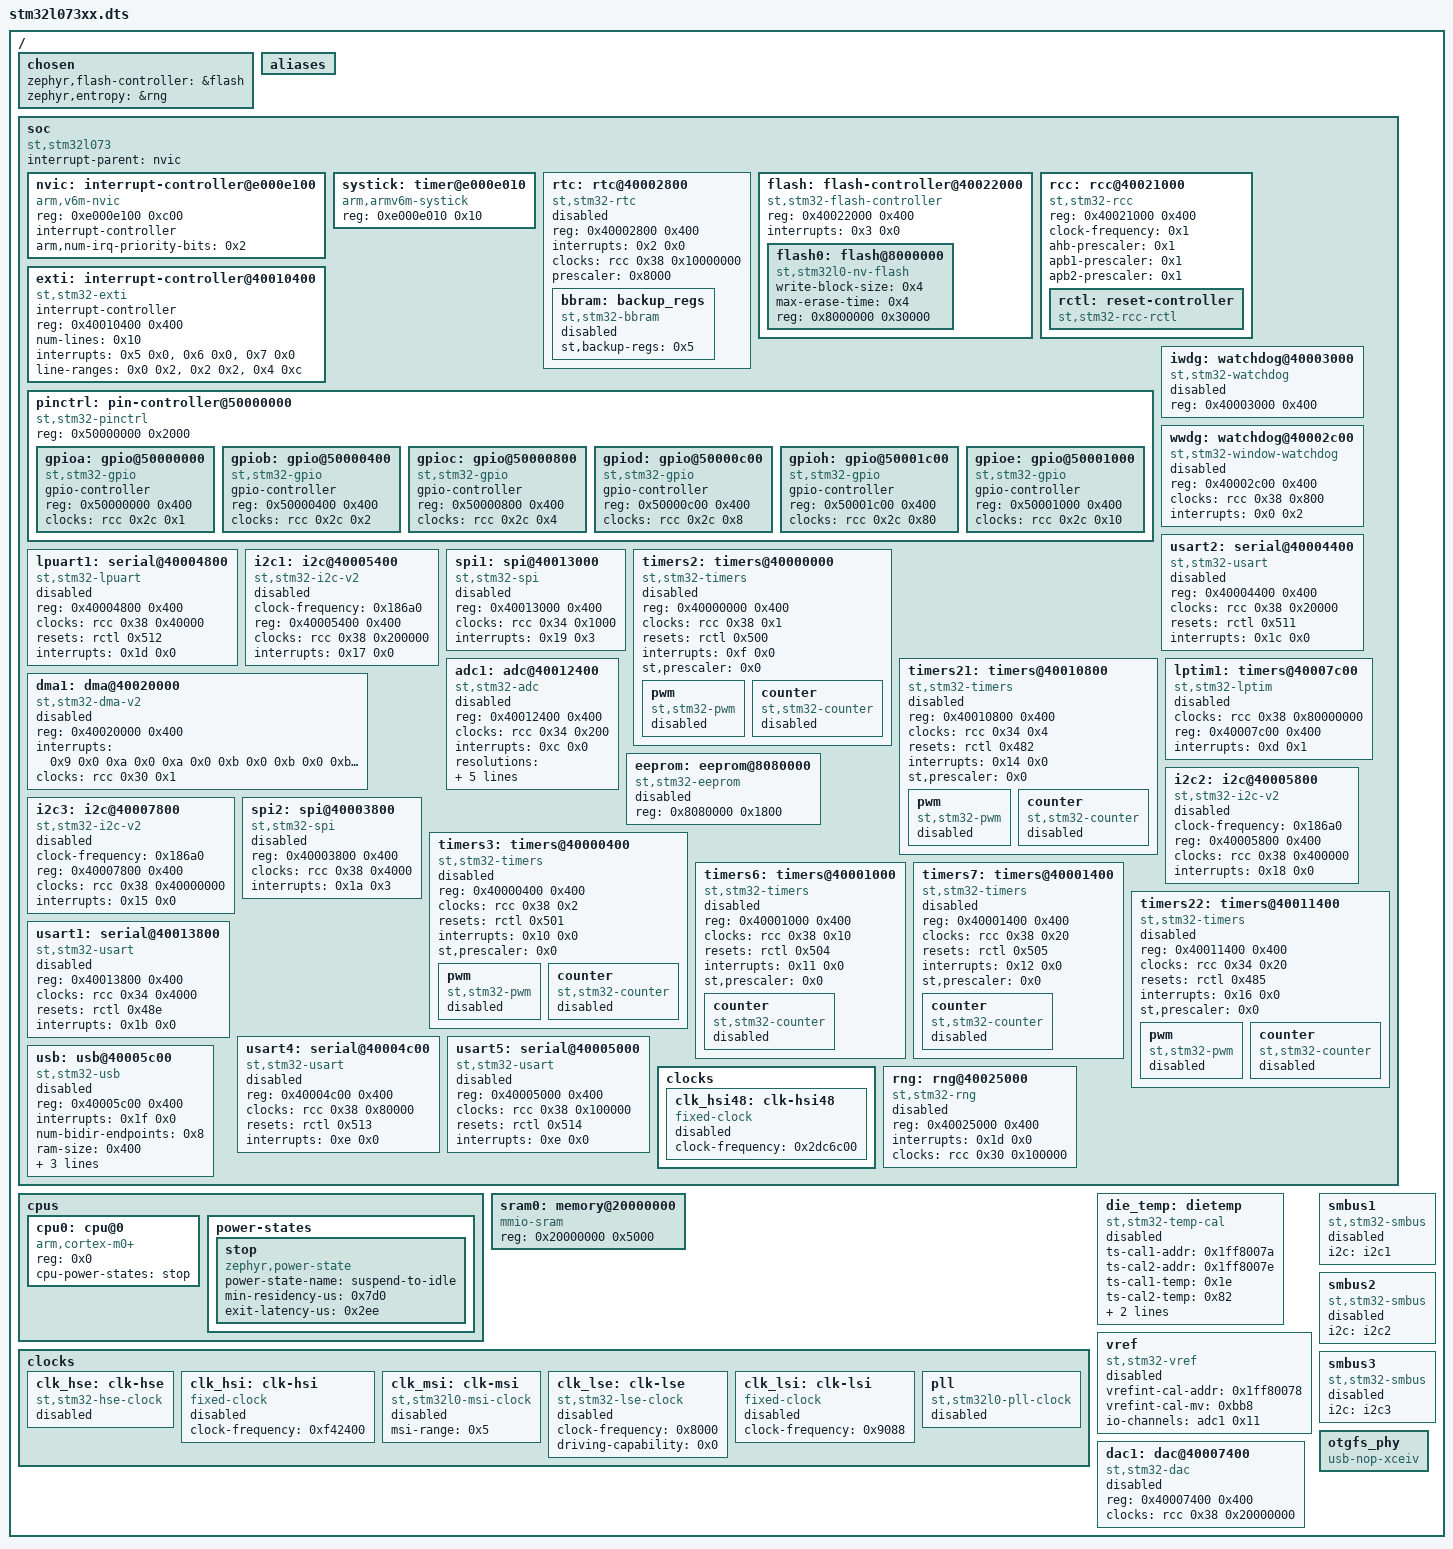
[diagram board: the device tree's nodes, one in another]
/dts-v1/;

/ {
	#address-cells = < 0x1 >;
	#size-cells = < 0x1 >;
	chosen {
		zephyr,flash-controller = &flash;
		zephyr,entropy = &rng;
	};
	aliases {
	};
	soc {
		#address-cells = < 0x1 >;
		#size-cells = < 0x1 >;
		compatible = "st,stm32l073", "st,stm32l0", "simple-bus";
		interrupt-parent = < &nvic >;
		ranges;
		nvic: interrupt-controller@e000e100 {
			#address-cells = < 0x1 >;
			compatible = "arm,v6m-nvic";
			reg = < 0xe000e100 0xc00 >;
			interrupt-controller;
			#interrupt-cells = < 0x2 >;
			arm,num-irq-priority-bits = < 0x2 >;
			phandle = < 0x1 >;
		};
		systick: timer@e000e010 {
			compatible = "arm,armv6m-systick";
			reg = < 0xe000e010 0x10 >;
		};
		rtc: rtc@40002800 {
			compatible = "st,stm32-rtc";
			reg = < 0x40002800 0x400 >;
			interrupts = < 0x2 0x0 >;
			clocks = < &rcc 0x38 0x10000000 >;
			prescaler = < 0x8000 >;
			status = "disabled";
			bbram: backup_regs {
				compatible = "st,stm32-bbram";
				st,backup-regs = < 0x5 >;
				status = "disabled";
			};
		};
		flash: flash-controller@40022000 {
			compatible = "st,stm32-flash-controller", "st,stm32f1-flash-controller";
			reg = < 0x40022000 0x400 >;
			interrupts = < 0x3 0x0 >;
			#address-cells = < 0x1 >;
			#size-cells = < 0x1 >;
			flash0: flash@8000000 {
				compatible = "st,stm32l0-nv-flash", "st,stm32-nv-flash", "soc-nv-flash";
				write-block-size = < 0x4 >;
				max-erase-time = < 0x4 >;
				reg = < 0x8000000 0x30000 >;
			};
		};
		rcc: rcc@40021000 {
			compatible = "st,stm32-rcc";
			#clock-cells = < 0x2 >;
			reg = < 0x40021000 0x400 >;
			clock-frequency = < 0x1 >;
			ahb-prescaler = < 0x1 >;
			apb1-prescaler = < 0x1 >;
			apb2-prescaler = < 0x1 >;
			phandle = < 0x2 >;
			rctl: reset-controller {
				compatible = "st,stm32-rcc-rctl";
				#reset-cells = < 0x1 >;
				phandle = < 0x3 >;
			};
		};
		exti: interrupt-controller@40010400 {
			compatible = "st,stm32-exti";
			interrupt-controller;
			#interrupt-cells = < 0x1 >;
			#address-cells = < 0x1 >;
			reg = < 0x40010400 0x400 >;
			num-lines = < 0x10 >;
			interrupts = < 0x5 0x0 >, < 0x6 0x0 >, < 0x7 0x0 >;
			interrupt-names = "line0-1", "line2-3", "line4-15";
			line-ranges = < 0x0 0x2 >, < 0x2 0x2 >, < 0x4 0xc >;
		};
		pinctrl: pin-controller@50000000 {
			compatible = "st,stm32-pinctrl";
			#address-cells = < 0x1 >;
			#size-cells = < 0x1 >;
			reg = < 0x50000000 0x2000 >;
			gpioa: gpio@50000000 {
				compatible = "st,stm32-gpio";
				gpio-controller;
				#gpio-cells = < 0x2 >;
				reg = < 0x50000000 0x400 >;
				clocks = < &rcc 0x2c 0x1 >;
			};
			gpiob: gpio@50000400 {
				compatible = "st,stm32-gpio";
				gpio-controller;
				#gpio-cells = < 0x2 >;
				reg = < 0x50000400 0x400 >;
				clocks = < &rcc 0x2c 0x2 >;
			};
			gpioc: gpio@50000800 {
				compatible = "st,stm32-gpio";
				gpio-controller;
				#gpio-cells = < 0x2 >;
				reg = < 0x50000800 0x400 >;
				clocks = < &rcc 0x2c 0x4 >;
			};
			gpiod: gpio@50000c00 {
				compatible = "st,stm32-gpio";
				gpio-controller;
				#gpio-cells = < 0x2 >;
				reg = < 0x50000c00 0x400 >;
				clocks = < &rcc 0x2c 0x8 >;
			};
			gpioh: gpio@50001c00 {
				compatible = "st,stm32-gpio";
				gpio-controller;
				#gpio-cells = < 0x2 >;
				reg = < 0x50001c00 0x400 >;
				clocks = < &rcc 0x2c 0x80 >;
			};
			gpioe: gpio@50001000 {
				compatible = "st,stm32-gpio";
				gpio-controller;
				#gpio-cells = < 0x2 >;
				reg = < 0x50001000 0x400 >;
				clocks = < &rcc 0x2c 0x10 >;
			};
		};
		iwdg: watchdog@40003000 {
			compatible = "st,stm32-watchdog";
			reg = < 0x40003000 0x400 >;
			status = "disabled";
		};
		wwdg: watchdog@40002c00 {
			compatible = "st,stm32-window-watchdog";
			reg = < 0x40002c00 0x400 >;
			clocks = < &rcc 0x38 0x800 >;
			interrupts = < 0x0 0x2 >;
			status = "disabled";
		};
		usart2: serial@40004400 {
			compatible = "st,stm32-usart", "st,stm32-uart";
			reg = < 0x40004400 0x400 >;
			clocks = < &rcc 0x38 0x20000 >;
			resets = < &rctl 0x511 >;
			interrupts = < 0x1c 0x0 >;
			status = "disabled";
		};
		lpuart1: serial@40004800 {
			compatible = "st,stm32-lpuart", "st,stm32-uart";
			reg = < 0x40004800 0x400 >;
			clocks = < &rcc 0x38 0x40000 >;
			resets = < &rctl 0x512 >;
			interrupts = < 0x1d 0x0 >;
			status = "disabled";
		};
		i2c1: i2c@40005400 {
			compatible = "st,stm32-i2c-v2";
			clock-frequency = < 0x186a0 >;
			#address-cells = < 0x1 >;
			#size-cells = < 0x0 >;
			reg = < 0x40005400 0x400 >;
			clocks = < &rcc 0x38 0x200000 >;
			interrupts = < 0x17 0x0 >;
			interrupt-names = "combined";
			status = "disabled";
			phandle = < 0x7 >;
		};
		spi1: spi@40013000 {
			compatible = "st,stm32-spi";
			#address-cells = < 0x1 >;
			#size-cells = < 0x0 >;
			reg = < 0x40013000 0x400 >;
			clocks = < &rcc 0x34 0x1000 >;
			interrupts = < 0x19 0x3 >;
			status = "disabled";
		};
		timers2: timers@40000000 {
			compatible = "st,stm32-timers";
			reg = < 0x40000000 0x400 >;
			clocks = < &rcc 0x38 0x1 >;
			resets = < &rctl 0x500 >;
			interrupts = < 0xf 0x0 >;
			interrupt-names = "global";
			st,prescaler = < 0x0 >;
			status = "disabled";
			pwm {
				compatible = "st,stm32-pwm";
				status = "disabled";
				#pwm-cells = < 0x3 >;
			};
			counter {
				compatible = "st,stm32-counter";
				status = "disabled";
			};
		};
		timers21: timers@40010800 {
			compatible = "st,stm32-timers";
			reg = < 0x40010800 0x400 >;
			clocks = < &rcc 0x34 0x4 >;
			resets = < &rctl 0x482 >;
			interrupts = < 0x14 0x0 >;
			interrupt-names = "global";
			st,prescaler = < 0x0 >;
			status = "disabled";
			pwm {
				compatible = "st,stm32-pwm";
				status = "disabled";
				#pwm-cells = < 0x3 >;
			};
			counter {
				compatible = "st,stm32-counter";
				status = "disabled";
			};
		};
		lptim1: timers@40007c00 {
			compatible = "st,stm32-lptim";
			clocks = < &rcc 0x38 0x80000000 >;
			#address-cells = < 0x1 >;
			#size-cells = < 0x0 >;
			reg = < 0x40007c00 0x400 >;
			interrupts = < 0xd 0x1 >;
			interrupt-names = "wakeup";
			status = "disabled";
		};
		adc1: adc@40012400 {
			compatible = "st,stm32-adc";
			reg = < 0x40012400 0x400 >;
			clocks = < &rcc 0x34 0x200 >;
			interrupts = < 0xc 0x0 >;
			status = "disabled";
			#io-channel-cells = < 0x1 >;
			resolutions = < 0x60630c 0x51630c 0x42630c 0x33630c >;
			sampling-times = < 0x2 0x4 0x8 0xd 0x14 0x28 0x50 0xa1 >;
			num-sampling-time-common-channels = < 0x1 >;
			st,adc-sequencer = < 0x0 >;
			phandle = < 0x6 >;
		};
		dma1: dma@40020000 {
			compatible = "st,stm32-dma-v2";
			#dma-cells = < 0x3 >;
			reg = < 0x40020000 0x400 >;
			interrupts = < 0x9 0x0 0xa 0x0 0xa 0x0 0xb 0x0 0xb 0x0 0xb 0x0 0xb 0x0 >;
			clocks = < &rcc 0x30 0x1 >;
			status = "disabled";
		};
		eeprom: eeprom@8080000 {
			compatible = "st,stm32-eeprom";
			status = "disabled";
			reg = < 0x8080000 0x1800 >;
		};
		i2c2: i2c@40005800 {
			compatible = "st,stm32-i2c-v2";
			clock-frequency = < 0x186a0 >;
			#address-cells = < 0x1 >;
			#size-cells = < 0x0 >;
			reg = < 0x40005800 0x400 >;
			clocks = < &rcc 0x38 0x400000 >;
			interrupts = < 0x18 0x0 >;
			interrupt-names = "combined";
			status = "disabled";
			phandle = < 0x8 >;
		};
		i2c3: i2c@40007800 {
			compatible = "st,stm32-i2c-v2";
			clock-frequency = < 0x186a0 >;
			#address-cells = < 0x1 >;
			#size-cells = < 0x0 >;
			reg = < 0x40007800 0x400 >;
			clocks = < &rcc 0x38 0x40000000 >;
			interrupts = < 0x15 0x0 >;
			interrupt-names = "combined";
			status = "disabled";
			phandle = < 0x9 >;
		};
		spi2: spi@40003800 {
			compatible = "st,stm32-spi";
			#address-cells = < 0x1 >;
			#size-cells = < 0x0 >;
			reg = < 0x40003800 0x400 >;
			clocks = < &rcc 0x38 0x4000 >;
			interrupts = < 0x1a 0x3 >;
			status = "disabled";
		};
		timers3: timers@40000400 {
			compatible = "st,stm32-timers";
			reg = < 0x40000400 0x400 >;
			clocks = < &rcc 0x38 0x2 >;
			resets = < &rctl 0x501 >;
			interrupts = < 0x10 0x0 >;
			interrupt-names = "global";
			st,prescaler = < 0x0 >;
			status = "disabled";
			pwm {
				compatible = "st,stm32-pwm";
				status = "disabled";
				#pwm-cells = < 0x3 >;
			};
			counter {
				compatible = "st,stm32-counter";
				status = "disabled";
			};
		};
		timers6: timers@40001000 {
			compatible = "st,stm32-timers";
			reg = < 0x40001000 0x400 >;
			clocks = < &rcc 0x38 0x10 >;
			resets = < &rctl 0x504 >;
			interrupts = < 0x11 0x0 >;
			interrupt-names = "global";
			st,prescaler = < 0x0 >;
			status = "disabled";
			counter {
				compatible = "st,stm32-counter";
				status = "disabled";
			};
		};
		timers7: timers@40001400 {
			compatible = "st,stm32-timers";
			reg = < 0x40001400 0x400 >;
			clocks = < &rcc 0x38 0x20 >;
			resets = < &rctl 0x505 >;
			interrupts = < 0x12 0x0 >;
			interrupt-names = "global";
			st,prescaler = < 0x0 >;
			status = "disabled";
			counter {
				compatible = "st,stm32-counter";
				status = "disabled";
			};
		};
		timers22: timers@40011400 {
			compatible = "st,stm32-timers";
			reg = < 0x40011400 0x400 >;
			clocks = < &rcc 0x34 0x20 >;
			resets = < &rctl 0x485 >;
			interrupts = < 0x16 0x0 >;
			interrupt-names = "global";
			st,prescaler = < 0x0 >;
			status = "disabled";
			pwm {
				compatible = "st,stm32-pwm";
				status = "disabled";
				#pwm-cells = < 0x3 >;
			};
			counter {
				compatible = "st,stm32-counter";
				status = "disabled";
			};
		};
		usart1: serial@40013800 {
			compatible = "st,stm32-usart", "st,stm32-uart";
			reg = < 0x40013800 0x400 >;
			clocks = < &rcc 0x34 0x4000 >;
			resets = < &rctl 0x48e >;
			interrupts = < 0x1b 0x0 >;
			status = "disabled";
		};
		usart4: serial@40004c00 {
			compatible = "st,stm32-usart", "st,stm32-uart";
			reg = < 0x40004c00 0x400 >;
			clocks = < &rcc 0x38 0x80000 >;
			resets = < &rctl 0x513 >;
			interrupts = < 0xe 0x0 >;
			status = "disabled";
		};
		usart5: serial@40005000 {
			compatible = "st,stm32-usart", "st,stm32-uart";
			reg = < 0x40005000 0x400 >;
			clocks = < &rcc 0x38 0x100000 >;
			resets = < &rctl 0x514 >;
			interrupts = < 0xe 0x0 >;
			status = "disabled";
		};
		clocks {
			clk_hsi48: clk-hsi48 {
				#clock-cells = < 0x0 >;
				compatible = "fixed-clock";
				clock-frequency = < 0x2dc6c00 >;
				status = "disabled";
			};
		};
		usb: usb@40005c00 {
			compatible = "st,stm32-usb";
			reg = < 0x40005c00 0x400 >;
			interrupts = < 0x1f 0x0 >;
			interrupt-names = "usb";
			num-bidir-endpoints = < 0x8 >;
			ram-size = < 0x400 >;
			maximum-speed = "full-speed";
			phys = < &otgfs_phy >;
			clocks = < &rcc 0x38 0x800000 >, < &rcc 0x6 0x13a4c >;
			status = "disabled";
		};
		rng: rng@40025000 {
			compatible = "st,stm32-rng";
			reg = < 0x40025000 0x400 >;
			interrupts = < 0x1d 0x0 >;
			clocks = < &rcc 0x30 0x100000 >;
			status = "disabled";
		};
	};
	cpus {
		#address-cells = < 0x1 >;
		#size-cells = < 0x0 >;
		cpu0: cpu@0 {
			device_type = "cpu";
			compatible = "arm,cortex-m0+";
			reg = < 0x0 >;
			cpu-power-states = < &stop >;
		};
		power-states {
			stop: stop {
				compatible = "zephyr,power-state";
				power-state-name = "suspend-to-idle";
				min-residency-us = < 0x7d0 >;
				exit-latency-us = < 0x2ee >;
				phandle = < 0x5 >;
			};
		};
	};
	sram0: memory@20000000 {
		compatible = "mmio-sram";
		reg = < 0x20000000 0x5000 >;
	};
	clocks {
		clk_hse: clk-hse {
			#clock-cells = < 0x0 >;
			compatible = "st,stm32-hse-clock";
			status = "disabled";
		};
		clk_hsi: clk-hsi {
			#clock-cells = < 0x0 >;
			compatible = "fixed-clock";
			clock-frequency = < 0xf42400 >;
			status = "disabled";
		};
		clk_msi: clk-msi {
			#clock-cells = < 0x0 >;
			compatible = "st,stm32l0-msi-clock";
			msi-range = < 0x5 >;
			status = "disabled";
		};
		clk_lse: clk-lse {
			#clock-cells = < 0x0 >;
			compatible = "st,stm32-lse-clock";
			clock-frequency = < 0x8000 >;
			driving-capability = < 0x0 >;
			status = "disabled";
		};
		clk_lsi: clk-lsi {
			#clock-cells = < 0x0 >;
			compatible = "fixed-clock";
			clock-frequency = < 0x9088 >;
			status = "disabled";
		};
		pll: pll {
			#clock-cells = < 0x0 >;
			compatible = "st,stm32l0-pll-clock";
			status = "disabled";
		};
	};
	die_temp: dietemp {
		compatible = "st,stm32-temp-cal";
		ts-cal1-addr = < 0x1ff8007a >;
		ts-cal2-addr = < 0x1ff8007e >;
		ts-cal1-temp = < 0x1e >;
		ts-cal2-temp = < 0x82 >;
		ts-cal-vrefanalog = < 0xbb8 >;
		io-channels = < &adc1 0x12 >;
		status = "disabled";
	};
	vref: vref {
		compatible = "st,stm32-vref";
		vrefint-cal-addr = < 0x1ff80078 >;
		vrefint-cal-mv = < 0xbb8 >;
		io-channels = < &adc1 0x11 >;
		status = "disabled";
	};
	smbus1: smbus1 {
		compatible = "st,stm32-smbus";
		#address-cells = < 0x1 >;
		#size-cells = < 0x0 >;
		i2c = < &i2c1 >;
		status = "disabled";
	};
	smbus2: smbus2 {
		compatible = "st,stm32-smbus";
		#address-cells = < 0x1 >;
		#size-cells = < 0x0 >;
		i2c = < &i2c2 >;
		status = "disabled";
	};
	smbus3: smbus3 {
		compatible = "st,stm32-smbus";
		#address-cells = < 0x1 >;
		#size-cells = < 0x0 >;
		i2c = < &i2c3 >;
		status = "disabled";
	};
	otgfs_phy: otgfs_phy {
		compatible = "usb-nop-xceiv";
		#phy-cells = < 0x0 >;
		phandle = < 0x4 >;
	};
	dac1: dac@40007400 {
		compatible = "st,stm32-dac";
		reg = < 0x40007400 0x400 >;
		clocks = < &rcc 0x38 0x20000000 >;
		status = "disabled";
		#io-channel-cells = < 0x1 >;
	};
};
